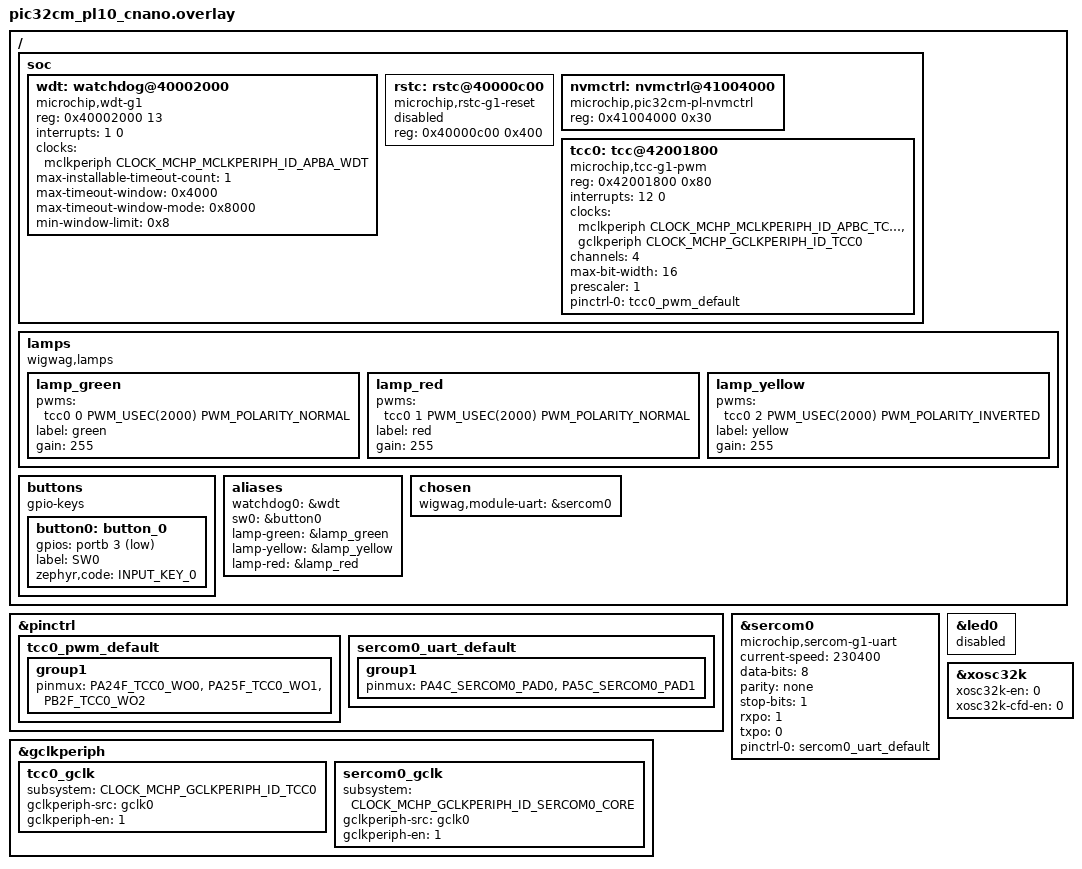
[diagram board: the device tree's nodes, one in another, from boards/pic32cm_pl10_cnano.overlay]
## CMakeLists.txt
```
# SPDX-License-Identifier: Apache-2.0

cmake_minimum_required(VERSION 3.20.0)

# Out-of-tree flash driver for PL10's NVMCTRL. A module rather than a patch to the pinned tree:
# `west update` reverts patches silently (firmware/patches/README.md), and this shape is what the
# upstream PR will be. Must come before find_package(Zephyr).
list(APPEND ZEPHYR_EXTRA_MODULES ${CMAKE_CURRENT_SOURCE_DIR}/modules/pic32cm-pl-nvmctrl)

# Gitignored credentials, merged automatically when present so `west build` needs no extra flags
# (D37). These are build-time *defaults*; stored settings win at runtime — see settings_store.c.
if(EXISTS ${CMAKE_CURRENT_SOURCE_DIR}/credentials.conf)
  list(APPEND EXTRA_CONF_FILE ${CMAKE_CURRENT_SOURCE_DIR}/credentials.conf)
  message(STATUS "wigwag: merging credentials.conf")
endif()

find_package(Zephyr REQUIRED HINTS $ENV{ZEPHYR_BASE})
project(wigwag)

target_sources(app PRIVATE
  src/main.c
  src/rnwf_at.c     # Zephyr-free core, also built for the host tests and the simulator
  src/rnwf_uart.c   # the Zephyr transport behind struct rnwf_at_io
  src/link.c        # link supervision: may the device believe what it shows?
  src/button.c      # pure debounce and press classification
  src/button_gpio.c # the polled GPIO binding
  src/lamp.c        # pure animation: (state, link, time) -> three levels
  src/lamp_pwm.c    # the Zephyr renderer: gamma, polarity, its own thread
  src/cmd.c         # pure command vocabulary and validation
  src/lineedit.c    # pure line editing: bytes -> lines. The swappable layer (see lineedit.h)
  src/console.c     # the Zephyr console adapter and command effects
  src/settings.c    # pure settings value handling
  src/settings_store.c  # persistence over NVS in the storage partition
  src/transport.c   # which transport is active, and may it be believed (D104)
  src/wdog.c        # pure liveness accounting: is every task that matters still beating?
  src/wdog_wdt.c    # the WDT peripheral, and the reset-cause report at boot
)
```

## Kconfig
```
# Build-time defaults for wigwag's configurable settings.
#
# These are *defaults*, not the configuration. Anything stored in the device's storage partition wins
# over them (settings_store.c), so a unit configured over the console keeps its settings across
# reflashes. They exist for two reasons: a bench build can bake in a known-good network so it comes
# up without typing anything, and a device that has never been configured has something coherent to
# fall back on rather than empty strings.
#
# Put real values in `firmware/credentials.conf`, which is gitignored and merged automatically by
# CMakeLists.txt when present. See credentials.conf.example. Never commit real credentials, and note
# that anything set here is a plaintext string in the firmware image.

menu "wigwag"

config WIGWAG_TRANSPORT_USB
	bool "Default to the wired (USB serial) transport"
	default y
	help
	  Which side owns the lamps on a device that has never been configured (ADR-0022, D120).

	  Defaults to the wire because that is the transport which needs no configuration: plug a fresh
	  device into a computer, start the daemon, and it works. Wi-Fi cannot work until an SSID and
	  passphrase have been set, so anyone using it is already configuring the device and can set
	  `transport wifi` in the same sitting.

	  Set this to n for a build that should come up wireless out of the box. Either way
	  `set transport usb|wifi` overrides it at runtime.

config WIGWAG_SSID
	string "Default Wi-Fi SSID"
	default ""

config WIGWAG_PASS
	string "Default Wi-Fi passphrase"
	default ""
	help
	  Leave empty for an open network. WPA-2 allows up to 63 characters.

config WIGWAG_SEC
	int "Default Wi-Fi security type (enum rnwf_sec_type)"
	default 0
	range 0 6

config WIGWAG_BROKER
	string "Default MQTT broker hostname"
	default "localhost"
	help
	  A hostname by preference rather than an address, per ADR-0013.

config WIGWAG_PORT
	int "Default MQTT broker port"
	default 1883
	range 1 65535

config WIGWAG_CLIENT
	string "Default MQTT client id"
	default "wigwag-1"

config WIGWAG_USER
	string "Default MQTT username"
	default ""

config WIGWAG_MQTTPASS
	string "Default MQTT password"
	default ""

endmenu

source "Kconfig.zephyr"
```

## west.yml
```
# wigwag firmware — west manifest
#
# T2 topology: this repository is the manifest repository, and the workspace topdir is the
# repo root, so `zephyr/`, `modules/` and `.west/` land beside `firmware/` and are gitignored.
# `firmware/` itself is the Zephyr application.
#
#   uv venv .venv && uv pip install --python .venv west
#   .venv/bin/west init -l firmware
#   .venv/bin/west update --narrow -o=--filter=blob:none
#
# ADR-0006: track mainline, but pinned to an explicit revision that is moved deliberately,
# never floating. ADR-0008: pull only the modules a PIC32C Cortex-M0+ build actually needs —
# a 2 GB checkout is not "minimum".
manifest:
  self:
    path: firmware

  remotes:
    - name: upstream
      url-base: https://github.com/zephyrproject-rtos

  projects:
    - name: zephyr
      remote: upstream
      # mainline `main` head on 2026-08-14.
      revision: 357467a011cd2557a1a3f0b4be83d817c4addc9b
      import:
        # Everything else in Zephyr's manifest is for other vendors, other arches, or
        # subsystems this design does not use (no networking — the RNWF02 owns it, ADR-0002).
        name-allowlist:
          - cmsis         # CMSIS-Core, Cortex-M
          - cmsis_6       # CMSIS 6, used by the newer SoC ports
          - hal_microchip # PIC32C SoC headers, base addresses, IRQ numbers
          - picolibc      # default C library for arm
```

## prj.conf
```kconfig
# wigwag firmware configuration.
#
# Rule 5: every option here costs SRAM out of 8 KB, so each one is justified.

# PWM for the lamps. PWM_MCHP_TCC_G1 then defaults y off
# DT_HAS_MICROCHIP_TCC_G1_PWM_ENABLED, which the board overlay provides.
CONFIG_PWM=y

# Interrupt-driven receive on the module UART. Polled receive drops bytes: at the module's native
# 230400 one arrives every 43 us and the SERCOM has no deep FIFO, so a loop that also renders lamps
# would lose characters mid-line. Costs the driver's per-instance IRQ state plus our own 256-byte ring.
CONFIG_UART_INTERRUPT_DRIVEN=y

# GPIO, for the button on SW0. The lamps do not need it — they are PWM — so this exists solely to
# read one pin. Costs the port-g1 driver plus one device instance for portb, tens of bytes of RAM.
# The input subsystem is deliberately *not* enabled: the button is polled (D86), so gpio-keys is
# used only as the devicetree description.
CONFIG_GPIO=y

# The logging subsystem costs a thread, its stack and a ring buffer — more than this
# needs. printk straight to the console is enough, and keeps the driver's LOG_ERR calls from
# pulling the subsystem in.
CONFIG_LOG=n

# Interrupt stack, tuned on measured evidence (Rule 5). The default 2048 B is the single largest
# item in an 8 KB budget, and a full exercise peaks at **264 bytes** — the only interrupt sources
# here are systick and SERCOM0 receive, neither of which nests. 1024 keeps a 4x margin over the
# measurement while returning 1 KB, which is 12.5% of all the SRAM on the part.
#
# Measure again before trusting this if an interrupt source is added: see prj_stacks.conf.
CONFIG_ISR_STACK_SIZE=1024

# Watchdog. The last hole in fail-visible: link.c supervises the module, the broker and the host, but
# nothing supervises link.c — if the AT loop wedges, supervision wedges with it and the lamps freeze
# on a confident, stale display. Costs the driver plus one device instance.
CONFIG_WATCHDOG=y

# CONFIG_HWINFO is deliberately *not* enabled, even though the reset cause is exactly the kind of
# diagnostic this device needs. hwinfo_mchp_g1.c reads PL10's RCAUSE at the wrong offset with JH's
# bit positions, so it returns a confident wrong answer (see wdog_wdt.c and
# docs/upstreaming-to-zephyr.md). wdog_wdt.c reads the register itself instead, which also keeps the
# driver, its device instance and the syscall shims out of an 8 KB part.

# Self-programming, so credentials (D37/D56) and brightness can live in the 4 KB storage partition
# instead of being compiled into the image. Costs the driver plus one device instance, and 24 bytes
# of RAM for its mutex and cached geometry. Erase and write stall the CPU while they run, which is
# why the erase duration is measured against the watchdog's 500 ms budget rather than assumed
# (ADR-0016). The driver is out-of-tree in firmware/modules/ because PL10's NVMCTRL is a different
# peripheral revision from the one mainline's Microchip flash driver targets.
CONFIG_FLASH=y

# Persistent settings in the 4 KB storage partition, so credentials and calibration survive a reflash
# and no longer need a rebuild to change (D37/D56). NVS rather than a hand-rolled record because the
# hard part is consistency across a power cut mid-write; costs its struct nvs_fs plus the ~300 bytes
# of RAM the settings strings need, which used to be flash literals costing nothing.
CONFIG_NVS=y

# `reboot` over the console, so applying Wi-Fi changes does not mean reaching for the cable. Costs
# nothing in RAM: sys_reboot() is a write to the Cortex-M reset register.
CONFIG_REBOOT=y
```

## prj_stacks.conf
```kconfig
# Stack measurement overlay — NOT for the shipping build.
#
# Rule 5 asks for measured footprint, not estimates, and stack sizes are the one part of this
# project's RAM that was chosen by feel. This turns them into numbers.
#
#   west build -p -b pic32cm_pl10_cnano firmware -d build/stacks \
#       -- -DEXTRA_CONF_FILE=prj_stacks.conf
#   west flash -d build/stacks
#   # then exercise the device HARD (see firmware/README.md) and read the console
#
# How it works: CONFIG_INIT_STACKS fills every stack with 0xaa before use — threads *and* the
# interrupt stack — so the high-water mark is wherever the pattern stops. THREAD_ANALYZER walks
# each stack looking for it and prints unused bytes per thread.
#
# The reported number is only as good as the exercise. A stack peak happens during the deepest
# call chain that has actually run, so anything not provoked is not measured: the AT connect
# script, a full-length command build (vsnprintf), the error and backoff paths, every lamp
# behaviour, and a link loss and recovery all need to occur before the numbers mean anything.

CONFIG_THREAD_ANALYZER=y
CONFIG_THREAD_ANALYZER_USE_PRINTK=y
CONFIG_THREAD_ANALYZER_AUTO=y
CONFIG_THREAD_ANALYZER_AUTO_INTERVAL=10

# THREAD_ANALYZER selects INIT_STACKS, THREAD_MONITOR and THREAD_STACK_INFO for us, and analyses
# the interrupt stack by default (CONFIG_THREAD_ANALYZER_ISR_STACK_USAGE) — which matters here,
# because z_interrupt_stacks is 2048 B, the single largest item in the budget.

# The analyzer's own thread needs room to run printk. This is measurement scaffolding, so it is
# allowed to be generous; it does not ship.
CONFIG_THREAD_ANALYZER_AUTO_STACK_SIZE=1024

# There is no MPU on PIC32CM PL10, so CONFIG_HW_STACK_PROTECTION is unavailable. The sentinel is
# the software substitute: a magic value at the bottom of each stack, checked periodically, which
# catches an overflow that has already happened rather than preventing it.
CONFIG_STACK_SENTINEL=y

# Names, so the report identifies threads instead of printing thread-object addresses.
CONFIG_THREAD_NAME=y
```

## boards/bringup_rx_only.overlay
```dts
/*
 * Bring-up diagnostic: listen on PA05, drive nothing. Answers "is the module's TX on PA05 or PA04?"
 * without ever transmitting.
 *
 *   west build -b pic32cm_pl10_cnano firmware -- \
 *       -DEXTRA_DTC_OVERLAY_FILE=boards/bringup_rx_only.overlay
 *
 * WHY THIS EXISTS. If the pair is reversed, PA04 -- which is always the transmitter, because
 * CTRLA.TXPO puts TxD on PAD[0] for every encoding (KB-000007252) -- is wired to the module's
 * UART1_TX, which is also an output. The AT client then retries AT+RST forever and every retry is
 * two 3.3 V drivers fighting on one net. Dropping PA04 from the pinmux leaves it an unmuxed,
 * high-impedance PORTA pin, so the wrong orientation costs nothing and the right one still works.
 *
 * HOW TO READ THE RESULT. Flash this, watch the console, then reset the module -- briefly ground
 * MCLR (PB04's wire; the add-on board pulls it up with R231 10k, DS50003575C Figure 5-4) or
 * power-cycle it. Then:
 *
 *   +BOOT arrives, the AT client leaves RESETTING   PA05 is on the module's UART1_TX.
 *                                                  The pair is the right way round.
 *   nothing ever arrives, RESETTING -> BACKOFF      PA05 is on the module's UART1_RX (an input,
 *                                                  hence the silence). Swap the two wires.
 *
 * The client cannot get past the first exchange in this build -- its AT+RST goes nowhere -- so
 * timeouts and a rising error count are expected and prove nothing either way. The single bit of
 * information wanted here is whether any byte at all arrives on PA05.
 *
 * Delete-on-sight material? No: keep it. Every board respin asks this same question once.
 *
 * SPDX-License-Identifier: Apache-2.0
 */

/*
 * Overrides group1's pinmux from the main overlay -- same property, later file wins. PA04 is simply
 * absent rather than reassigned, which is what makes it high-Z: nothing claims it, and porta is
 * status = "disabled" so no GPIO driver takes it either.
 */
&sercom0_uart_default {
	group1 {
		pinmux = <PA5C_SERCOM0_PAD1>;
	};
};
```

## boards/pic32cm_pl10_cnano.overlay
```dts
/*
 * D49 — TCC0 PWM enablement for PIC32CM PL10.
 *
 * Mainline Zephyr has the driver (drivers/pwm/pwm_mchp_tcc_g1.c) and the binding
 * (dts/bindings/pwm/microchip,tcc-g1-pwm.yaml), and hal_microchip has the pinmux macros and
 * both clock IDs — but the PL10 devicetree defines no TC or TCC node at all, so nothing binds.
 * Everything below is the missing board/SoC layer, in the shape mainline already uses for the
 * sibling JH01 family (dts/arm/microchip/pic32c/pic32cm_jh/common/pic32cm_5164_jh.dtsi).
 *
 * Values verified rather than copied — the JH01 numbers are wrong for this part:
 *   reg           0x42001800   TCC0_BASE_ADDRESS, hal_microchip pic32cm6408pl10048.h
 *   interrupts    12           TCC0_IRQn, same header; datasheet Table 4-3
 *   channels      4            TCC_CC[4] / TCC_CCBUF[4], component/tcc.h
 *   max-bit-width 16           TCC_COUNT_Msk == 0x0000FFFF — the JH01's TCC is 24-bit, this
 *                              one is not, and claiming 24 would silently accept periods the
 *                              counter cannot represent
 *
 * SPDX-License-Identifier: Apache-2.0
 */

#include <zephyr/dt-bindings/pwm/pwm.h>

/ {
	soc {
		/*
		 * Watchdog and reset controller — the fifth and sixth PL10 devicetree nodes this
		 * project has had to add. Driver (wdt_mchp_g1.c) and binding both exist upstream and
		 * the JH, SG and SAM families instantiate them; this family does not. Addresses and
		 * the IRQ come from hal_microchip's pic32cm6408pl10048.h and happen to match JH
		 * exactly (WDT 0x40002000 IRQ 1, RSTC 0x40000c00), and the WDT is the same module
		 * (U2251), so the timeout limits carry over: PER maxes at CYC16384, hence 16384 ms.
		 */
		wdt: watchdog@40002000 {
			compatible = "microchip,wdt-g1";
			reg = <0x40002000 13>;
			interrupts = <1 0>;
			interrupt-names = "wdt-ew";
			clocks = <&mclkperiph CLOCK_MCHP_MCLKPERIPH_ID_APBA_WDT>;
			clock-names = "mclk";
			max-installable-timeout-count = <1>;
			max-timeout-window = <0x4000>;		/* 16384 ms */
			max-timeout-window-mode = <0x8000>;	/* 32768 ms */
			min-window-limit = <0x8>;		/* 8 ms */
			status = "okay";
		};

		/*
		 * Reset controller: the address of record for RCAUSE, which is how the firmware reports
		 * *why* it rebooted. On an appliance whose only output is three lamps, "reset by
		 * watchdog" is the difference between a diagnosable fault and a mystery.
		 *
		 * Left **disabled** on purpose. Enabling it binds hwinfo_mchp_g1.c, which was written
		 * against the JH revision of this peripheral and reads the wrong register at the wrong
		 * offset with the wrong bit positions on PL10 — it answers, and the answer is wrong.
		 * wdog_wdt.c reads RCAUSE itself, at the address given here. Enable this once the
		 * upstream driver understands this family (docs/upstreaming-to-zephyr.md).
		 */
		rstc: rstc@40000c00 {
			compatible = "microchip,rstc-g1-reset";
			reg = <0x40000c00 0x400>;
			status = "disabled";
		};

		/*
		 * NVMCTRL — the seventh PL10 devicetree node this project has added, and the first
		 * needing a driver written from scratch rather than enabled: the in-tree
		 * microchip,nvmctrl-g1-flash targets module U2409, whose page-buffer command set this
		 * revision does not have (firmware/modules/pic32cm-pl-nvmctrl).
		 *
		 * Base 0x41004000 from hal_microchip's pic32cm6408pl10048.h, cross-checked against the
		 * datasheet's own programming sequence, which cites NVMCTRL_CTRLB at 0x4100_4004
		 * (§6.5.7.1.7) — base + 4, since offset 0 is reserved on this revision.
		 *
		 * A sibling of flash0 rather than its parent, which is the shape every other Zephyr
		 * flash controller uses. PL10 declares flash0 directly under /soc and devicetree cannot
		 * reparent an existing node, so partition-to-device resolution stays broken until that
		 * is fixed upstream. Consumers pass this device explicitly with
		 * FIXED_PARTITION_OFFSET(); see docs/upstreaming-to-zephyr.md.
		 */
		nvmctrl: nvmctrl@41004000 {
			compatible = "microchip,pic32cm-pl-nvmctrl";
			reg = <0x41004000 0x30>;
			status = "okay";
		};

		tcc0: tcc@42001800 {
			compatible = "microchip,tcc-g1-pwm";
			reg = <0x42001800 0x80>;
			interrupts = <12 0>;
			clocks = <&mclkperiph CLOCK_MCHP_MCLKPERIPH_ID_APBC_TCC0>,
				 <&gclkperiph CLOCK_MCHP_GCLKPERIPH_ID_TCC0>;
			clock-names = "mclk", "gclk";
			channels = <4>;
			max-bit-width = <16>;
			/*
			 * GCLK0 is 24 MHz (board dts). At DIV1 a 16-bit counter reaches down to
			 * 24e6/65536 = 366 Hz, so the 500 Hz lamp carrier below fits with 48000
			 * counts of dimming resolution and no prescaler.
			 */
			prescaler = <1>;
			#pwm-cells = <3>;
			pinctrl-0 = <&tcc0_pwm_default>;
			pinctrl-names = "default";
			status = "okay";
		};
	};

	/*
	 * The three lamps (D46: TCC0 WO0/WO1/WO2). On the Curiosity Nano:
	 *
	 *   green   WO0   PA24   external LED + 470R-1k to GND      active high
	 *   red     WO1   PA25   external LED + 470R-1k to GND      active high
	 *   yellow  WO2   PB02   the board's own yellow LED         active LOW
	 *
	 * **The polarity cells do nothing without firmware/patches/0001-*.patch applied.**
	 * Mainline's microchip,tcc-g1-pwm.yaml names its third pwm-cell "polarity", while Zephyr
	 * resolves flags via DT_PHA_BY_IDX_OR(..., flags, 0) — so an unpatched tree silently
	 * discards them. main.c prints the resolved flags at boot for exactly that reason (D74).
	 *
	 * PB02's active-low wiring is the board's, not the product's: its user guide §4.1 says
	 * "driving the connected I/O line to GND will activate the LED" while mainline's board
	 * devicetree claims GPIO_ACTIVE_HIGH, which is a second upstream bug (D72).
	 */
	lamps {
		compatible = "wigwag,lamps";

		/*
		 * Polarity is per lamp, and on this board it genuinely differs: the on-board yellow
		 * LED is wired active low (D72), while externally wired lamps go pin -> resistor ->
		 * LED -> GND and are active high. The PCB will be uniformly active high through
		 * low-side FETs (D26), so nothing may assume a single polarity.
		 */
		/*
		 * `gain` is per-lamp calibration, measured by eye, not derived from anything. All three
		 * start at 255 (no correction); lower whichever lamp looks brighter than its siblings at
		 * the same state. On this bench the on-board yellow is an SMD part with a fixed series
		 * resistor while green and red are hand-wired through their own resistors, so they have
		 * no reason to match.
		 */
		lamp_green: lamp_green {
			pwms = <&tcc0 0 PWM_USEC(2000) PWM_POLARITY_NORMAL>;
			label = "green";
			gain = <255>;
		};

		lamp_red: lamp_red {
			pwms = <&tcc0 1 PWM_USEC(2000) PWM_POLARITY_NORMAL>;
			label = "red";
			gain = <255>;
		};

		lamp_yellow: lamp_yellow {
			pwms = <&tcc0 2 PWM_USEC(2000) PWM_POLARITY_INVERTED>;
			label = "yellow";
			gain = <255>;
		};
	};

	/*
	 * SW0, the board's user switch. Active low — pressing it connects the pin to GND — and there
	 * is no external pull-up, so the internal one is required (user guide §4.2).
	 *
	 * Described with gpio-keys for the standard shape, but read by polling rather than through
	 * the input subsystem: PL10's devicetree has no EIC node, so a pin interrupt would mean
	 * enabling an interrupt controller to save nothing on a button (D86). GPIO_ACTIVE_LOW means
	 * gpio_pin_get_dt() returns 1 when pressed, so no inversion in the code.
	 *
	 * PB03 is shared with the on-board debugger (DBG2), which tri-states it when inactive.
	 */
	buttons {
		compatible = "gpio-keys";

		button0: button_0 {
			gpios = <&portb 3 (GPIO_PULL_UP | GPIO_ACTIVE_LOW)>;
			label = "SW0";
			zephyr,code = <INPUT_KEY_0>;
		};
	};

	aliases {
		/*
		 * watchdog0 is the name every in-tree consumer uses, and the JH dtsi defines it at SoC
		 * level. Defined here instead because PL10 has no wdt node upstream to hang it off.
		 */
		watchdog0 = &wdt;
		sw0 = &button0;
		lamp-green = &lamp_green;
		lamp-yellow = &lamp_yellow;
		lamp-red = &lamp_red;
	};

	/*
	 * Which UART the RNWF02 lives on. A chosen node rather than an alias because it names a
	 * role in the system, and keeps the AT client free of board-specific labels.
	 */
	chosen {
		wigwag,module-uart = &sercom0;
	};
};

&pinctrl {
	tcc0_pwm_default: tcc0_pwm_default {
		group1 {
			/*
			 * Three lamps on one TCC: WO0 = PA24, WO1 = PA25, WO2 = PB02, all
			 * peripheral function F. PA24/PA25 are the 32.768 kHz crystal's I/O lines,
			 * which the board routes to the edge connector by default (cut straps J107
			 * and J108 intact), so they are free without rework.
			 */
			pinmux = <PA24F_TCC0_WO0>, <PA25F_TCC0_WO1>, <PB2F_TCC0_WO2>;
		};
	};

	/*
	 * The module UART. SERCOM0 on the PCB too (D46), so the dev board exercises the same
	 * peripheral the product uses.
	 *
	 * PA04/PA05 chosen by elimination on this board: the debugger holds PB00/PB01 (the CDC
	 * console), PA20 (SWDIO), PA31 (SWCLK), PB03 (SW0) and PA30 (RESET); PA24/PA25 are the
	 * 32.768 kHz crystal footprint; PB08/PB09 are the touch button; and PA08-PA15 sit in the
	 * MVIO domain powered from VDDIO2, which is a needless dependency for a UART.
	 *
	 * Note porta is left status = "disabled". The pinctrl driver builds its port address table
	 * with DT_NODE_EXISTS rather than a status check, so muxing works without instantiating a
	 * GPIO device we never use.
	 */
	sercom0_uart_default: sercom0_uart_default {
		group1 {
			pinmux = <PA4C_SERCOM0_PAD0>, <PA5C_SERCOM0_PAD1>;
		};
	};
};

/*
 * SERCOM0 as the module UART: PAD0 transmits, PAD1 receives, matching the board's own sercom1
 * console wiring (txpo = 0, rxpo = 1).
 *
 * **TX cannot be moved off PAD0.** CTRLA.TXPO selects only where XCK/RTS/CTS land; every encoding
 * puts TxD on PAD[0] (SERCOM USART Control A, and Microchip KB-000007252 states it outright). RXPO
 * *is* free to pick any of PAD[0..3]. So PA04 is always the transmitter here, and a module wired
 * the other way round has to be rewired — there is no devicetree fix.
 *
 * 230400 because that is the module's factory default, not a choice: RNWF02 UART1 is "Default:
 * 230,400 baud, 8N1, no flow control" (Wi-Fi Module Data Sheet DS70005544C, Table 2-1, pins 14 and
 * 19), and the add-on board's own PC-companion instructions say the same (DS50003575C §3.3.1). At
 * 115200 the firmware and a factory module are mutually deaf, which presents exactly like a
 * miswired pair: AT+RST, no +BOOT, RESETTING -> BACKOFF forever.
 */
&sercom0 {
	compatible = "microchip,sercom-g1-uart";
	#address-cells = <1>;
	#size-cells = <0>;
	current-speed = <230400>;
	data-bits = <8>;
	parity = "none";
	stop-bits = "1";
	rxpo = <1>;
	txpo = <0>;
	pinctrl-0 = <&sercom0_uart_default>;
	pinctrl-names = "default";
	status = "okay";
};

/*
 * The generic clock channel is set up from devicetree children at init —
 * DT_FOREACH_CHILD(DT_NODELABEL(gclkperiph), ...) in
 * drivers/clock_control/clock_control_mchp_pic32cm_pl.c — so without this entry the TCC has a
 * bus clock, binds cleanly, and produces nothing.
 */
&gclkperiph {
	tcc0_gclk {
		subsystem = <CLOCK_MCHP_GCLKPERIPH_ID_TCC0>;
		gclkperiph-src = "gclk0";
		gclkperiph-en = <1>;
	};

	/* Same requirement for SERCOM0: no channel here means a UART that never clocks. */
	sercom0_gclk {
		subsystem = <CLOCK_MCHP_GCLKPERIPH_ID_SERCOM0_CORE>;
		gclkperiph-src = "gclk0";
		gclkperiph-en = <1>;
	};
};

/*
 * PB02 carries both the Curiosity Nano's LED0 and TCC0/WO2 (datasheet §2.3), which is what
 * makes this spike need no external wiring. Hand the pin to TCC0 and say so in the
 * devicetree, rather than leaving two drivers able to claim it.
 */
&led0 {
	status = "disabled";
};

/*
 * Disable the 32.768 kHz crystal oscillator — **this is what makes PA24 and PA25 usable at all.**
 *
 * They are XTAL32K1 and XTAL32K2, and datasheet §13.5.1 is unconditional: "the XTAL32K1 and XTAL32K2
 * pins are automatically configured when the XOSC32K oscillator is enabled". The board devicetree
 * enables it (`xosc32k-en = <1>`), so TCC0's pinmux on both pins was accepted and then silently
 * ignored — no error anywhere, because the override happens in the oscillator rather than in PORT.
 *
 * Verified by a controlled A/B on hardware rather than by reading: identical firmware and wiring,
 * only this property changed, lamps driven to full by the power-on test. Both pins dead with the
 * oscillator enabled, both working with it disabled.
 *
 * Worth knowing that §13.4.2.2 claims the override is mode-dependent — that in External Clock mode
 * only XTAL32K1 is taken and XTAL32K2 "may be used as a GPIO pin". This board *is* in that mode
 * (`xosc32k-xtal-en` defaults to 0, confirmed in devicetree_generated.h), and PA25 is taken anyway.
 * Do not trust that sentence on this part.
 *
 * The board's crystal is also not connected by default — its user guide routes these I/O lines to the
 * edge connector, and attaching the crystal means cutting straps J107/J108 — so the oscillator is
 * enabled, unusable and unused (`gclkgen0` is sourced from OSCHF).
 *
 * Measured, so as not to overstate the cost: enabling it adds **no** boot time here. Reset to first
 * console byte was 1624 ms enabled against 1621 ms disabled. The driver's WAIT_FOR on XOSC32KRDY uses
 * a 1000000 us timeout that looks like a one-second stall; it is not.
 *
 * Nothing here needs it. Re-enable only alongside moving the green and red lamps off PA24/PA25.
 */
&xosc32k {
	xosc32k-en = <0>;
	xosc32k-cfd-en = <0>;
};
```

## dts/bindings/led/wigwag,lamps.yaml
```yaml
# Copyright (c) 2026 wigwag
# SPDX-License-Identifier: Apache-2.0

description: |
  The three wigwag lamps, with per-lamp calibration.

  Why this exists rather than using pwm-leds: LEDs of different colours have quite different
  luminous efficiency at the same duty cycle, so equal perceptual levels do not look equally bright.
  Correcting that is *calibration* - a fixed property of a particular board and its parts, exactly
  like polarity - so it belongs in devicetree.

  It is deliberately not the same mechanism as `wigwag/brightness`, which is a runtime *preference*
  carried over MQTT. Sharing one mechanism would mean calibration gets clobbered whenever somebody
  turns the device down for the evening.

  pwm-leds cannot express this: its child binding allows only `label` and `pwms`.

compatible: "wigwag,lamps"

include: base.yaml

child-binding:
  description: One lamp.

  properties:
    pwms:
      required: true
      type: phandle-array
      description: |
        The PWM channel driving this lamp, as <&controller channel period flags>. Flags carry
        polarity, which differs per lamp on some boards.

    label:
      type: string
      description: Human-readable name, for diagnostics.

    gain:
      type: int
      default: 255
      description: |
        Per-lamp brightness calibration, 0-255, applied to the perceptual level before gamma.

        255 means "use the level as-is". Lower it for a lamp that is brighter than its siblings at
        the same level, so the three can be balanced against each other. Applied multiplicatively
        with the runtime brightness, and measured by eye - there is no way to derive it from a
        datasheet, because it depends on the LED, its series resistor and its diffuser.
```

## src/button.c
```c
/*
 * Button debounce and press classification. See button.h.
 *
 * SPDX-License-Identifier: Apache-2.0
 */

#include "button.h"

#include <string.h>

void button_init(struct button *b)
{
	memset(b, 0, sizeof(*b));
}

struct button_result button_sample(struct button *b, bool pressed, uint32_t now_ms)
{
	struct button_result r = { .event = BUTTON_EVENT_NONE, .ms = 0 };

	if (!b->have_raw) {
		/*
		 * Adopt the first sample without emitting anything. A device that boots with the
		 * button held down must not report a press it never saw begin — and on this board
		 * the pin is shared with the debugger, so the first reading after reset is not
		 * necessarily a user action.
		 */
		b->have_raw = true;
		b->raw = pressed;
		b->stable = pressed;
		b->raw_since_ms = now_ms;
		b->pressed_at_ms = now_ms;
		return r;
	}

	if (pressed != b->raw) {
		/* Raw edge: restart the settling window. */
		if (b->raw != b->stable) {
			/*
			 * The previous edge never settled, so it was chatter rather than a change.
			 * Counted because a switch that chatters more over time is a real symptom.
			 */
			b->chatter++;
		}
		b->raw = pressed;
		b->raw_since_ms = now_ms;
		return r;
	}

	/* Raw is steady. Has it been steady long enough to believe? */
	if (b->raw != b->stable && (uint32_t)(now_ms - b->raw_since_ms) >= BUTTON_DEBOUNCE_MS) {
		b->stable = b->raw;

		if (b->stable) {
			b->pressed_at_ms = now_ms;
			b->long_reported = false;
		} else {
			/*
			 * Released. Report the duration from the debounced press, so the number the
			 * host sees is the settled hold time rather than including chatter.
			 */
			b->presses++;
			r.event = BUTTON_EVENT_PRESS;
			r.ms = (uint32_t)(now_ms - b->pressed_at_ms);
			return r;
		}
	}

	/*
	 * Still held: announce the long threshold as it passes, not on release. Waiting for release
	 * would mean holding the button with no feedback and no way to know whether it took.
	 */
	if (b->stable && !b->long_reported &&
	    (uint32_t)(now_ms - b->pressed_at_ms) >= BUTTON_LONG_MS) {
		b->long_reported = true;
		r.event = BUTTON_EVENT_LONG;
		r.ms = (uint32_t)(now_ms - b->pressed_at_ms);
	}

	return r;
}
```

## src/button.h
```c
/*
 * Button debounce and press classification — pure logic, no Zephyr, no GPIO.
 *
 * Takes raw samples plus a timestamp and produces settled events. Sampled rather than
 * interrupt-driven: a press lasts ~100 ms so 10 ms sampling is invisible, debounce needs tens of
 * milliseconds of settling regardless, and PL10's devicetree has no EIC node so an interrupt would
 * mean enabling a whole interrupt controller to save nothing (D86).
 *
 * Two consumers, deliberately separate:
 *   - every settled press is published raw with its duration, and the host decides what it means
 *     (D35, CONTEXT.md's `wigwag/button` topic);
 *   - a long hold is reported locally *while still held*, which is what will enter provisioning
 *     mode (D58) — you need to know it registered before you let go.
 *
 * SPDX-License-Identifier: Apache-2.0
 */

#ifndef BUTTON_H
#define BUTTON_H

#include <stdbool.h>
#include <stdint.h>

/*
 * 20 ms of settling. Tactile switches chatter for a few milliseconds; 20 ms is comfortably past
 * that and still far below the ~100 ms floor of a deliberate human press, so no real press is lost.
 */
#define BUTTON_DEBOUNCE_MS 20U

/* 3 s to enter provisioning mode — long enough that it cannot be hit by accident (D58). */
#define BUTTON_LONG_MS 3000U

enum button_event {
	BUTTON_EVENT_NONE = 0,
	/** Settled release. `ms` carries how long it was held. */
	BUTTON_EVENT_PRESS,
	/** The long-hold threshold passed while still held. Fires once per press. */
	BUTTON_EVENT_LONG,
};

struct button_result {
	enum button_event event;
	uint32_t ms;
};

struct button {
	bool raw;		/* last raw sample */
	bool stable;		/* debounced state: true = pressed */
	bool long_reported;	/* the long event has already fired for this press */
	bool have_raw;		/* a first sample has been seen */
	uint32_t raw_since_ms;	/* when the raw sample last changed */
	uint32_t pressed_at_ms;	/* when the debounced state became pressed */

	uint32_t presses;	/* diagnostics */
	uint32_t chatter;	/* raw changes rejected by debounce */
};

void button_init(struct button *b);

/**
 * Feed one sample.
 *
 * @param pressed raw reading, already corrected for active-low wiring
 * @param now_ms  monotonic milliseconds
 *
 * Returns at most one event per call. A press that crosses the long threshold produces
 * BUTTON_EVENT_LONG while held and BUTTON_EVENT_PRESS on release, in that order — the release
 * still reports its true duration, because the host is entitled to the raw fact (D35).
 */
struct button_result button_sample(struct button *b, bool pressed, uint32_t now_ms);

static inline bool button_is_down(const struct button *b)
{
	return b->stable;
}

#endif /* BUTTON_H */
```

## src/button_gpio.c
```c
/*
 * Zephyr GPIO binding for the button. See button_gpio.h.
 *
 * SPDX-License-Identifier: Apache-2.0
 */

#include "button_gpio.h"

#include <zephyr/device.h>
#include <zephyr/drivers/gpio.h>
#include <zephyr/sys/printk.h>

static const struct gpio_dt_spec sw = GPIO_DT_SPEC_GET(DT_ALIAS(sw0), gpios);

int button_gpio_init(void)
{
	int ret;

	if (!gpio_is_ready_dt(&sw)) {
		printk("wigwag: button not ready\n");
		return -ENODEV;
	}

	/*
	 * GPIO_INPUT plus the devicetree's GPIO_PULL_UP. The pull-up is not optional on this board:
	 * SW0 has no external one, so without it the pin floats and reads as noise (user guide §4.2).
	 */
	ret = gpio_pin_configure_dt(&sw, GPIO_INPUT);
	if (ret != 0) {
		printk("wigwag: button configure failed (%d)\n", ret);
		return ret;
	}

	printk("wigwag: button on %s pin %u\n", sw.port->name, sw.pin);
	return 0;
}

bool button_gpio_pressed(void)
{
	int val = gpio_pin_get_dt(&sw);

	/*
	 * Negative means a read error. Treat it as released: a fault that reported "pressed" would
	 * publish a press every debounce window, and a flood of false presses is worse than silence
	 * on a topic the host is entitled to trust.
	 */
	return val > 0;
}
```

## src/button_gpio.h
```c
/*
 * Zephyr GPIO binding for the button: the hardware half of button.c.
 *
 * Polled, not interrupt-driven — see button.h and D86. That keeps this file to a pin read, with no
 * ISR, no callback registration and nothing to make ISR-safe.
 *
 * SPDX-License-Identifier: Apache-2.0
 */

#ifndef BUTTON_GPIO_H
#define BUTTON_GPIO_H

#include <stdbool.h>

/** Configure the button pin. Returns 0, or -ENODEV if it is missing or not ready. */
int button_gpio_init(void);

/**
 * Read the button.
 *
 * True means pressed. Devicetree carries the active-low wiring, so no inversion happens here.
 * A read failure reports "not pressed": a stuck-on button would publish a continuous stream of
 * presses, which is worse than missing one.
 */
bool button_gpio_pressed(void);

#endif /* BUTTON_GPIO_H */
```

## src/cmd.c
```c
/*
 * Console command parsing. See cmd.h.
 *
 * SPDX-License-Identifier: Apache-2.0
 */

#include "cmd.h"

#include <string.h>

struct key_name {
	const char *name;
	enum cmd_key key;
	bool numeric;
	bool secret;
};

/*
 * The whole settable surface, in one table, so `show`, `set` and the help text cannot drift apart.
 * `numeric` keys are validated at parse time; a bad number is refused rather than stored as zero.
 */
/* Not ARRAY_SIZE(): this file stays free of Zephyr headers so the host tests can build it. */
#define N_KEYS (sizeof(keys) / sizeof((keys)[0]))

static const struct key_name keys[] = {
	{ "ssid",     CMD_KEY_SSID,     false, false },
	{ "pass",     CMD_KEY_PASS,     false, true  },
	{ "sec",      CMD_KEY_SEC,      true,  false },
	{ "broker",   CMD_KEY_BROKER,   false, false },
	{ "port",     CMD_KEY_PORT,     true,  false },
	{ "client",   CMD_KEY_CLIENT,   false, false },
	{ "user",     CMD_KEY_USER,     false, false },
	{ "mqttpass", CMD_KEY_MQTTPASS, false, true  },
	{ "transport", CMD_KEY_TRANSPORT, false, false },
};

static const struct key_name *key_lookup(const char *name)
{
	size_t i;

	for (i = 0; i < N_KEYS; i++) {
		if (strcmp(keys[i].name, name) == 0) {
			return &keys[i];
		}
	}

	return NULL;
}

bool cmd_is_host_activity(const struct cmd *c)
{
	if (c == NULL) {
		return false;
	}

	/* `host on` claims; `host off` is its opposite and must not. */
	if (c->kind == CMD_HOST) {
		return c->num != 0U;
	}

	return c->kind == CMD_STATE;
}

bool cmd_key_is_secret(enum cmd_key key)
{
	size_t i;

	for (i = 0; i < N_KEYS; i++) {
		if (keys[i].key == key) {
			return keys[i].secret;
		}
	}

	/* Unknown keys are treated as secret: the safe direction is to print less, not more. */
	return true;
}

const char *cmd_key_str(enum cmd_key key)
{
	size_t i;

	for (i = 0; i < N_KEYS; i++) {
		if (keys[i].key == key) {
			return keys[i].name;
		}
	}

	return "?";
}

static bool is_space(char c)
{
	return c == ' ' || c == '\t';
}

/*
 * Strict decimal. No sign, no prefix, no trailing junk, no overflow — a console that accepted "12x"
 * as 12 would let a typo configure a port number nobody intended.
 */
static bool parse_u32(const char *s, uint32_t *out)
{
	uint32_t v = 0;
	size_t digits = 0;

	if (s == NULL) {
		return false;
	}

	while (*s != '\0') {
		uint32_t d;

		if (*s < '0' || *s > '9') {
			return false;
		}

		d = (uint32_t)(*s - '0');

		if (v > (0xFFFFFFFFU - d) / 10U) {
			return false;	/* would overflow */
		}

		v = (v * 10U) + d;
		digits++;
		s++;
	}

	if (digits == 0U) {
		return false;
	}

	*out = v;

	return true;
}

/** Advance past a token, NUL-terminate it, and return the start of whatever follows. */
static char *split(char *p, char **token)
{
	while (is_space(*p)) {
		p++;
	}

	*token = p;

	while (*p != '\0' && !is_space(*p)) {
		p++;
	}

	if (*p != '\0') {
		*p = '\0';
		p++;
	}

	return p;
}

static bool parse_gain(char *rest, struct cmd *out)
{
	char *which;
	char *value;

	rest = split(rest, &which);
	(void)split(rest, &value);

	if (strcmp(which, "green") == 0) {
		out->lamp = LAMP_GREEN;
	} else if (strcmp(which, "yellow") == 0) {
		out->lamp = LAMP_YELLOW;
	} else if (strcmp(which, "red") == 0) {
		out->lamp = LAMP_RED;
	} else {
		return false;
	}

	/*
	 * Reuse the brightness parser: gain and brightness occupy the same 0-255 space and the same
	 * meaning (a perceptual scale, not a duty cycle — D89), so they should refuse the same inputs.
	 */
	{
		uint8_t level;

		if (!lamp_brightness_parse(value, &level)) {
			return false;
		}

		out->num = level;
		out->num_valid = true;
	}

	return true;
}

bool cmd_parse(char *line, struct cmd *out)
{
	char *verb;
	char *rest;
	size_t len;

	memset(out, 0, sizeof(*out));

	if (line == NULL) {
		out->kind = CMD_NONE;
		return true;
	}

	/* Strip trailing CR/LF and nothing else: a trailing space could belong to a passphrase. */
	len = strlen(line);
	while (len > 0U && (line[len - 1U] == '\r' || line[len - 1U] == '\n')) {
		line[--len] = '\0';
	}

	rest = split(line, &verb);

	if (verb[0] == '\0') {
		out->kind = CMD_NONE;
		return true;
	}

	if (strcmp(verb, "help") == 0 || strcmp(verb, "?") == 0) {
		out->kind = CMD_HELP;
		return true;
	}

	if (strcmp(verb, "show") == 0) {
		out->kind = CMD_SHOW;
		return true;
	}

	if (strcmp(verb, "save") == 0) {
		out->kind = CMD_SAVE;
		return true;
	}

	if (strcmp(verb, "clear") == 0) {
		out->kind = CMD_CLEAR;
		return true;
	}

	if (strcmp(verb, "reboot") == 0) {
		out->kind = CMD_REBOOT;
		return true;
	}

	if (strcmp(verb, "state") == 0) {
		char *value;

		(void)split(rest, &value);
		out->kind = CMD_STATE;

		/*
		 * The bare-word entry point, sharing its table with the JSON one so the two carriers
		 * cannot disagree about the vocabulary (ADR-0018).
		 */
		return wigwag_state_parse_word(value, &out->state);
	}

	if (strcmp(verb, "brightness") == 0) {
		char *value;
		uint8_t level;

		(void)split(rest, &value);
		out->kind = CMD_BRIGHTNESS;

		if (!lamp_brightness_parse(value, &level)) {
			return false;
		}

		out->num = level;
		out->num_valid = true;

		return true;
	}

	if (strcmp(verb, "test") == 0) {
		char *what;

		(void)split(rest, &what);

		/* Spelled out rather than implied, and `module` comes first: it is the one that needs no
		 * configuration, so it is the one to reach for when nothing works yet.
		 */
		if (strcmp(what, "module") == 0) {
			out->kind = CMD_TEST_MODULE;
			return true;
		}

		if (strcmp(what, "scan") == 0) {
			out->kind = CMD_TEST_SCAN;
			return true;
		}

		if (strcmp(what, "wifi") == 0) {
			out->kind = CMD_TEST_WIFI;
			return true;
		}

		if (strcmp(what, "broker") == 0) {
			out->kind = CMD_TEST_BROKER;
			return true;
		}

		out->kind = CMD_TEST_WIFI;

		return false;
	}

	if (strcmp(verb, "host") == 0) {
		char *value;

		(void)split(rest, &value);
		out->kind = CMD_HOST;

		if (strcmp(value, "on") == 0) {
			out->num = 1;
		} else if (strcmp(value, "off") == 0) {
			out->num = 0;
		} else {
			return false;
		}

		out->num_valid = true;

		return true;
	}

	if (strcmp(verb, "echo") == 0) {
		char *value;

		(void)split(rest, &value);
		out->kind = CMD_ECHO;

		if (strcmp(value, "on") == 0) {
			out->num = 1;
		} else if (strcmp(value, "off") == 0) {
			out->num = 0;
		} else {
			return false;
		}

		out->num_valid = true;

		return true;
	}

	if (strcmp(verb, "gain") == 0) {
		out->kind = CMD_GAIN;
		return parse_gain(rest, out);
	}

	if (strcmp(verb, "set") == 0) {
		const struct key_name *k;
		char *name;

		rest = split(rest, &name);
		k = key_lookup(name);

		out->kind = CMD_SET;

		if (k == NULL) {
			out->key = CMD_KEY_NONE;
			return false;
		}

		out->key = k->key;

		/*
		 * The value is the rest of the line verbatim, after one run of separating whitespace.
		 * Wi-Fi passphrases may contain spaces, so tokenising here would silently truncate a
		 * legal passphrase at its first space — and the failure would look like a wrong password.
		 */
		while (is_space(*rest)) {
			rest++;
		}

		out->value = rest;

		if (k->numeric) {
			if (!parse_u32(rest, &out->num)) {
				return false;
			}
			out->num_valid = true;
		}

		/*
		 * An empty value is legal and meaningful: `set pass` with nothing after it is how you
		 * configure an open network, and `set user` with nothing clears a broker username.
		 */
		return true;
	}

	out->kind = CMD_UNKNOWN;

	return false;
}
```

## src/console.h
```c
/*
 * The console adapter: the Zephyr and effects half of the command console.
 *
 * Owns the console UART, feeds bytes to lineedit.c, hands complete lines to cmd.c, and applies the
 * result — to the settings store, to the lamps, or to the displayed state. The three layers are
 * separate on purpose (see lineedit.h): this file and cmd.c hold the decisions, lineedit.c is the
 * piece designed to be replaced if a richer CLI ever earns its RAM.
 *
 * Receive is interrupt-driven into a small ring, for the same reason rnwf_uart.c is (D77): at 115200
 * a byte lands every 87 us and this SERCOM has no deep FIFO, so a 10 ms poll loop would keep only the
 * last byte of each interval. Typing survives polling; **pasting a passphrase does not**, and pasting
 * a 63-character passphrase is exactly what someone will do.
 *
 * SPDX-License-Identifier: Apache-2.0
 */

#ifndef CONSOLE_H
#define CONSOLE_H

#include "settings.h"
#include "transport.h"

/**
 * Take over receive on the console UART and start accepting commands.
 *
 * @p s and @p t are borrowed and must outlive the console: @p s is the live settings the commands
 * edit, and @p t is told whenever a host speaks, which is what lets the wired path be trusted at all
 * (D104). Returns 0, or -ENODEV if the console UART is missing, in which case the device runs exactly
 * as it did before: unconfigurable, but working.
 */
int console_init(struct wigwag_settings *s, struct transport *t);

/** Drain received bytes and execute any complete lines. Call from the service loop. */
void console_poll(void);

/**
 * Start a Wi-Fi connectivity test, implemented by main.c because it owns the AT client.
 *
 * Returns 0 if a test was started, or a negative errno explaining why not. Must return immediately:
 * the test is advanced by the service loop, so the console stays responsive and the watchdog keeps
 * being fed (ADR-0016) instead of a 30-second command blocking everything.
 */
int wifi_test_start(void);

/**
 * Reset the module and wait for +BOOT: the liveness check that needs no settings.
 *
 * Returns 0 once started, -EALREADY if a test is already running, or -ENODEV if the module UART
 * will not bind. Progress and the verdict go to the console as the service loop advances it.
 */
int module_test_start(void);

/** Scan for visible networks (AT+WSCN=1). Needs no settings. Same return codes as above. */
int scan_test_start(void);

/** The full path: associate, connect to the broker, subscribe. -EINVAL with no SSID stored. */
int broker_test_start(void);

#endif /* CONSOLE_H */
```

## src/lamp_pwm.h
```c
/*
 * Zephyr renderer for the lamps: the PWM and threading half of lamp.c.
 *
 * Owns a thread so a long AT transmission cannot stutter an animation. uart_poll_out() blocks its
 * caller for up to ~24 ms on a full-length command (rnwf_uart.c), which is two and a half frames —
 * visible as a hitch in the breathe. Rendering therefore runs at a cooperative priority above the
 * AT loop.
 *
 * Gamma correction and per-lamp polarity live here rather than in lamp.c, so the animation stays a
 * pure function of time and the hardware's quirks stay at the edge.
 *
 * SPDX-License-Identifier: Apache-2.0
 */

#ifndef LAMP_PWM_H
#define LAMP_PWM_H

#include "lamp.h"

/** Bind the three lamps and start the render thread. Returns 0, or -ENODEV if a lamp is missing. */
int lamp_pwm_init(void);

/**
 * Adopt a new state. Timestamped internally, because WAIT's escalation is measured from when the
 * state arrived, not from boot.
 *
 * Idempotent: re-setting the current state does not restart the escalation timer, so a stream of
 * repeated BUSY heartbeats cannot hold WAIT off forever.
 */
void lamp_pwm_set_state(enum wigwag_state state);

/**
 * Set the runtime master brightness, 0-255, from `wigwag/brightness`.
 *
 * Scales what the lamps report. It cannot silence the fail-visible pattern, which floors at
 * LAMP_FAULT_MIN_BRIGHTNESS — see lamp.h.
 */
void lamp_pwm_set_brightness(uint8_t brightness);

/** Update the link condition. False overrides every state with the fail-visible pattern. */
void lamp_pwm_set_link(bool trusted);

/**
 * Set one lamp's calibration gain, 0-255.
 *
 * Devicetree supplies the starting values (D91) and remains the record of what a *board* needs, but
 * calibration is judged by eye on an assembled unit — which is impossible if changing it requires a
 * rebuild. The console sets this live and the settings store remembers it (D37/D56).
 */
void lamp_pwm_set_gain(enum lamp_id lamp, uint8_t gain);

#endif /* LAMP_PWM_H */
```
